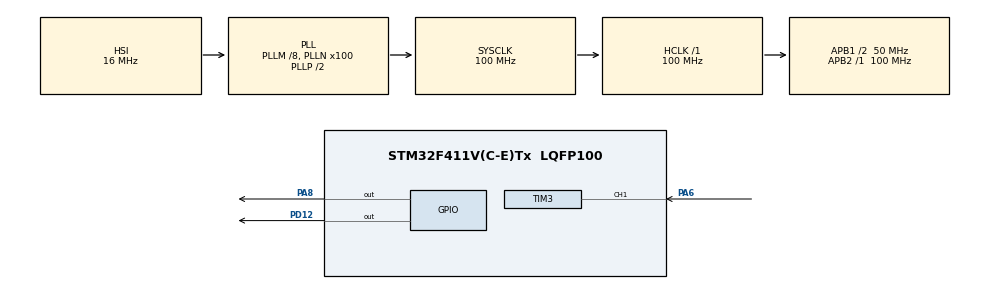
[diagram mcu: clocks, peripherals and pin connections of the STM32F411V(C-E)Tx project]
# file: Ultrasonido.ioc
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Mcu.Family=STM32F4
Mcu.Name=STM32F411V(C-E)Tx
Mcu.Package=LQFP100
NVIC.PriorityGroup=NVIC_PRIORITYGROUP_0
NVIC.TIM3_IRQn=true\:0\:0\:false\:false\:true\:true\:true\:true
PA13.Mode=Serial_Wire
PA13.Signal=SYS_JTMS-SWDIO
PA14.Mode=Serial_Wire
PA14.Signal=SYS_JTCK-SWCLK
PA6.Signal=S_TIM3_CH1
PA8.Signal=GPIO_Output
PD12.Signal=GPIO_Output
ProjectManager.HeapSize=0x200
ProjectManager.StackSize=0x400
ProjectManager.TargetToolchain=STM32CubeIDE
RCC.48MHZClocksFreq_Value=25000000
RCC.AHBFreq_Value=100000000
RCC.APB1CLKDivider=RCC_HCLK_DIV2
RCC.APB1Freq_Value=50000000
RCC.APB1TimFreq_Value=100000000
RCC.APB2Freq_Value=100000000
RCC.APB2TimFreq_Value=100000000
RCC.CortexFreq_Value=100000000
RCC.HCLKFreq_Value=100000000
RCC.HSE_VALUE=8000000
RCC.HSI_VALUE=16000000
RCC.LSE_VALUE=32768
RCC.PLLI2SM=5
RCC.PLLI2SN=200
RCC.PLLM=8
RCC.PLLN=100
RCC.PLLQ=8
RCC.SYSCLKFreq_VALUE=100000000
RCC.SYSCLKSource=RCC_SYSCLKSOURCE_PLLCLK
RCC.VCOOutputFreq_Value=200000000
SH.S_TIM3_CH1.0=TIM3_CH1,Input_Capture1_from_TI1
TIM3.Channel-Input_Capture1_from_TI1=TIM_CHANNEL_1
TIM3.ICFilter_CH1=4
TIM3.Period=65535
TIM3.Prescaler=100-1
VP_TIM3_VS_ClockSourceINT.Mode=Internal
board=STM32F411E-DISCO

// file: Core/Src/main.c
/* USER CODE BEGIN Header */
/**
  ******************************************************************************
  * @file           : main.c
  * @brief          : Main program body
  ******************************************************************************
  * @attention
  *
  * Copyright (c) 2025 STMicroelectronics.
  * All rights reserved.
  *
  * This software is licensed under terms that can be found in the LICENSE file
  * in the root directory of this software component.
  * If no LICENSE file comes with this software, it is provided AS-IS.
  *
  ******************************************************************************
  */
/* USER CODE END Header */
#include "main.h"

/* USER CODE BEGIN PD */
// Define los pines para TRIG y ECHO
#define TRIG_PIN GPIO_PIN_8
#define TRIG_PORT GPIOA
#define ECHO_PIN GPIO_PIN_6
#define ECHO_PORT GPIOA

// Define el pin del LED
#define LED_PIN GPIO_PIN_12
#define LED_PORT GPIOD

/* USER CODE END PD */

TIM_HandleTypeDef htim3;

void SystemClock_Config(void);
static void MX_GPIO_Init(void);
static void MX_TIM3_Init(void);
/* USER CODE BEGIN PFP */
void delayMicroseconds(uint16_t microseconds) {
    __HAL_TIM_SET_COUNTER(&htim3, 0); // Reinicia el contador
    while (__HAL_TIM_GET_COUNTER(&htim3) < microseconds); // Espera
}

// Función para medir la distancia
float getDistance() {
    uint32_t startTime = 0, endTime = 0;

    // Genera el pulso TRIG (10µs)
    HAL_GPIO_WritePin(TRIG_PORT, TRIG_PIN, GPIO_PIN_SET);
    delayMicroseconds(10);
    HAL_GPIO_WritePin(TRIG_PORT, TRIG_PIN, GPIO_PIN_RESET);

    // Espera el inicio del pulso ECHO
    while (HAL_GPIO_ReadPin(ECHO_PORT, ECHO_PIN) == GPIO_PIN_RESET);

    startTime = __HAL_TIM_GET_COUNTER(&htim3); // Marca el tiempo inicial

    // Espera el final del pulso ECHO
    while (HAL_GPIO_ReadPin(ECHO_PORT, ECHO_PIN) == GPIO_PIN_SET);

    endTime = __HAL_TIM_GET_COUNTER(&htim3); // Marca el tiempo final

    // Calcula la duración del pulso (en microsegundos)
    uint32_t duration = endTime - startTime;

    // Calcula la distancia en cm (velocidad del sonido: 34300 cm/s)
    return (duration * 0.0343) / 2;
}

/* USER CODE END PFP */

int main(void)
{

  /* MCU Configuration--------------------------------------------------------*/

  /* Reset of all peripherals, Initializes the Flash interface and the Systick. */
  HAL_Init();

  /* Configure the system clock */
  SystemClock_Config();

  /* Initialize all configured peripherals */
  MX_GPIO_Init();
  MX_TIM3_Init();
  /* USER CODE BEGIN 2 */

  HAL_TIM_Base_Start(&htim3); // Inicia el temporizador

      while (1) {
          float distance = getDistance(); // Mide la distancia

          if (distance < 10.0) { // Si la distancia es menor a 10 cm
              HAL_GPIO_WritePin(LED_PORT, LED_PIN, GPIO_PIN_SET); // Enciende el LED
          } else {
              HAL_GPIO_WritePin(LED_PORT, LED_PIN, GPIO_PIN_RESET); // Apaga el LED
          }

          HAL_Delay(100); // Espera 100 ms antes de la siguiente medición
      }
}

void SystemClock_Config(void)
{
  RCC_OscInitTypeDef RCC_OscInitStruct = {0};
  RCC_ClkInitTypeDef RCC_ClkInitStruct = {0};

  /** Configure the main internal regulator output voltage
  */
  __HAL_RCC_PWR_CLK_ENABLE();
  __HAL_PWR_VOLTAGESCALING_CONFIG(PWR_REGULATOR_VOLTAGE_SCALE1);

  /** Initializes the RCC Oscillators according to the specified parameters
  * in the RCC_OscInitTypeDef structure.
  */
  RCC_OscInitStruct.OscillatorType = RCC_OSCILLATORTYPE_HSI;
  RCC_OscInitStruct.HSIState = RCC_HSI_ON;
  RCC_OscInitStruct.HSICalibrationValue = RCC_HSICALIBRATION_DEFAULT;
  RCC_OscInitStruct.PLL.PLLState = RCC_PLL_ON;
  RCC_OscInitStruct.PLL.PLLSource = RCC_PLLSOURCE_HSI;
  RCC_OscInitStruct.PLL.PLLM = 8;
  RCC_OscInitStruct.PLL.PLLN = 100;
  RCC_OscInitStruct.PLL.PLLP = RCC_PLLP_DIV2;
  RCC_OscInitStruct.PLL.PLLQ = 8;
  if (HAL_RCC_OscConfig(&RCC_OscInitStruct) != HAL_OK)
  {
    Error_Handler();
  }

  /** Initializes the CPU, AHB and APB buses clocks
  */
  RCC_ClkInitStruct.ClockType = RCC_CLOCKTYPE_HCLK|RCC_CLOCKTYPE_SYSCLK
                              |RCC_CLOCKTYPE_PCLK1|RCC_CLOCKTYPE_PCLK2;
  RCC_ClkInitStruct.SYSCLKSource = RCC_SYSCLKSOURCE_PLLCLK;
  RCC_ClkInitStruct.AHBCLKDivider = RCC_SYSCLK_DIV1;
  RCC_ClkInitStruct.APB1CLKDivider = RCC_HCLK_DIV2;
  RCC_ClkInitStruct.APB2CLKDivider = RCC_HCLK_DIV1;

  if (HAL_RCC_ClockConfig(&RCC_ClkInitStruct, FLASH_LATENCY_3) != HAL_OK)
  {
    Error_Handler();
  }
}

static void MX_TIM3_Init(void)
{

  TIM_ClockConfigTypeDef sClockSourceConfig = {0};
  TIM_MasterConfigTypeDef sMasterConfig = {0};
  TIM_IC_InitTypeDef sConfigIC = {0};

  htim3.Instance = TIM3;
  htim3.Init.Prescaler = 100-1;
  htim3.Init.CounterMode = TIM_COUNTERMODE_UP;
  htim3.Init.Period = 65535;
  htim3.Init.ClockDivision = TIM_CLOCKDIVISION_DIV1;
  htim3.Init.AutoReloadPreload = TIM_AUTORELOAD_PRELOAD_DISABLE;
  if (HAL_TIM_Base_Init(&htim3) != HAL_OK)
  {
    Error_Handler();
  }
  sClockSourceConfig.ClockSource = TIM_CLOCKSOURCE_INTERNAL;
  if (HAL_TIM_ConfigClockSource(&htim3, &sClockSourceConfig) != HAL_OK)
  {
    Error_Handler();
  }
  if (HAL_TIM_IC_Init(&htim3) != HAL_OK)
  {
    Error_Handler();
  }
  sMasterConfig.MasterOutputTrigger = TIM_TRGO_RESET;
  sMasterConfig.MasterSlaveMode = TIM_MASTERSLAVEMODE_DISABLE;
  if (HAL_TIMEx_MasterConfigSynchronization(&htim3, &sMasterConfig) != HAL_OK)
  {
    Error_Handler();
  }
  sConfigIC.ICPolarity = TIM_INPUTCHANNELPOLARITY_RISING;
  sConfigIC.ICSelection = TIM_ICSELECTION_DIRECTTI;
  sConfigIC.ICPrescaler = TIM_ICPSC_DIV1;
  sConfigIC.ICFilter = 4;
  if (HAL_TIM_IC_ConfigChannel(&htim3, &sConfigIC, TIM_CHANNEL_1) != HAL_OK)
  {
    Error_Handler();
  }

}

static void MX_GPIO_Init(void)
{
  GPIO_InitTypeDef GPIO_InitStruct = {0};

  /* GPIO Ports Clock Enable */
  __HAL_RCC_GPIOA_CLK_ENABLE();
  __HAL_RCC_GPIOD_CLK_ENABLE();

  /*Configure GPIO pin Output Level */
  HAL_GPIO_WritePin(GPIOD, GPIO_PIN_12, GPIO_PIN_RESET);

  /*Configure GPIO pin Output Level */
  HAL_GPIO_WritePin(GPIOA, GPIO_PIN_8, GPIO_PIN_RESET);

  /*Configure GPIO pin : PD12 */
  GPIO_InitStruct.Pin = GPIO_PIN_12;
  GPIO_InitStruct.Mode = GPIO_MODE_OUTPUT_PP;
  GPIO_InitStruct.Pull = GPIO_NOPULL;
  GPIO_InitStruct.Speed = GPIO_SPEED_FREQ_LOW;
  HAL_GPIO_Init(GPIOD, &GPIO_InitStruct);

  /*Configure GPIO pin : PA8 */
  GPIO_InitStruct.Pin = GPIO_PIN_8;
  GPIO_InitStruct.Mode = GPIO_MODE_OUTPUT_PP;
  GPIO_InitStruct.Pull = GPIO_NOPULL;
  GPIO_InitStruct.Speed = GPIO_SPEED_FREQ_LOW;
  HAL_GPIO_Init(GPIOA, &GPIO_InitStruct);

}

void Error_Handler(void)
{
  __disable_irq();
  while (1)
  {
  }
}
